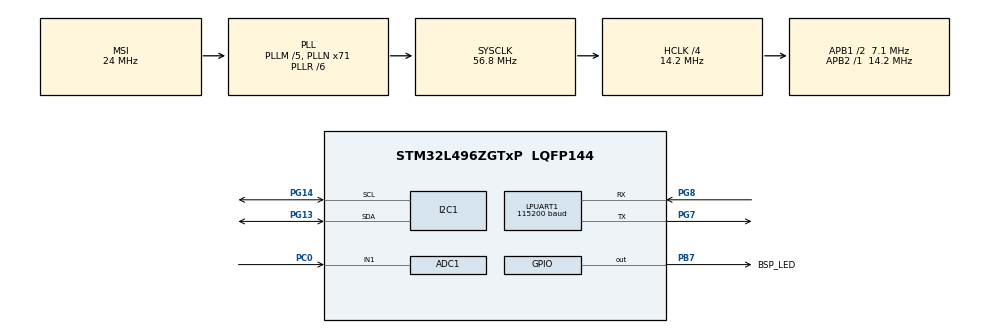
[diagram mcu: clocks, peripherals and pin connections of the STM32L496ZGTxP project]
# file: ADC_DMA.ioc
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ADC1.Channel-0\#ChannelRegularConversion=ADC_CHANNEL_1
ADC1.NbrOfConversionFlag=1
ADC1.OffsetNumber-0\#ChannelRegularConversion=ADC_OFFSET_NONE
ADC1.Rank-0\#ChannelRegularConversion=1
ADC1.SamplingTime-0\#ChannelRegularConversion=ADC_SAMPLETIME_2CYCLES_5
ADC1.master=1
Dma.ADC1.0.Direction=DMA_PERIPH_TO_MEMORY
Dma.ADC1.0.Instance=DMA1_Channel1
Dma.ADC1.0.MemDataAlignment=DMA_MDATAALIGN_WORD
Dma.ADC1.0.MemInc=DMA_MINC_ENABLE
Dma.ADC1.0.Mode=DMA_CIRCULAR
Dma.ADC1.0.PeriphDataAlignment=DMA_PDATAALIGN_WORD
Dma.ADC1.0.PeriphInc=DMA_PINC_DISABLE
Dma.ADC1.0.Priority=DMA_PRIORITY_LOW
Dma.Request0=ADC1
I2C1.Timing=0x00101A26
LPUART1.BaudRate=115200
LPUART1.WordLength=UART_WORDLENGTH_8B
Mcu.Family=STM32L4
Mcu.Name=STM32L496ZGTxP
Mcu.Package=LQFP144
NVIC.DMA1_Channel1_IRQn=true\:0\:0\:false\:false\:true\:false\:true\:true
NVIC.PriorityGroup=NVIC_PRIORITYGROUP_4
PB7.GPIO_Label=BSP_LED
PB7.Signal=GPIO_Output
PC0.Signal=ADCx_IN1
PG13.Mode=I2C
PG13.Signal=I2C1_SDA
PG14.Mode=I2C
PG14.Signal=I2C1_SCL
PG7.Mode=Asynchronous
PG7.Signal=LPUART1_TX
PG8.Mode=Asynchronous
PG8.Signal=LPUART1_RX
ProjectManager.HeapSize=0x200
ProjectManager.StackSize=0x400
ProjectManager.TargetToolchain=STM32CubeIDE
RCC.48MHZClocksFreq_Value=24000000
RCC.ADCFreq_Value=48000000
RCC.AHBCLKDivider=RCC_SYSCLK_DIV4
RCC.AHBFreq_Value=14200000
RCC.APB1CLKDivider=RCC_HCLK_DIV2
RCC.APB1Freq_Value=7100000
RCC.APB1TimFreq_Value=14200000
RCC.APB2Freq_Value=14200000
RCC.APB2TimFreq_Value=14200000
RCC.CortexFreq_Value=14200000
RCC.HCLKFreq_Value=14200000
RCC.HSE_VALUE=8000000
RCC.HSI48_VALUE=48000000
RCC.HSI_VALUE=16000000
RCC.LSE_VALUE=32768
RCC.MSIClockRange=RCC_MSIRANGE_9
RCC.MSI_VALUE=24000000
RCC.PLLM=5
RCC.PLLMUL=RCC_PLL_MUL9
RCC.PLLN=71
RCC.PLLR=RCC_PLLR_DIV6
RCC.PLLSAI1N=20
RCC.PRESCALERUSB=RCC_USBCLKSOURCE_PLL_DIV1_5
RCC.SYSCLKFreq_VALUE=56800000
RCC.SYSCLKSource=RCC_SYSCLKSOURCE_PLLCLK
RCC.SYSCLKSourceVirtual=RCC_SYSCLKSOURCE_PLLCLK
RCC.USBFreq_Value=48000000
RCC.VCOOutputFreq_Value=340800000
SH.ADCx_IN1.0=ADC1_IN1,IN1-Single-Ended
board=NUCLEO-L496ZG-P

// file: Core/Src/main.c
/* USER CODE BEGIN Header */
/**
 ******************************************************************************
 * @file           : main.c
 * @brief          : Main program body
 ******************************************************************************
 * @attention
 *
 * Copyright (c) 2023 STMicroelectronics.
 * All rights reserved.
 *
 * This software is licensed under terms that can be found in the LICENSE file
 * in the root directory of this software component.
 * If no LICENSE file comes with this software, it is provided AS-IS.
 *
 ******************************************************************************
 */
/* USER CODE END Header */
#include "main.h"

/* USER CODE BEGIN Includes */
#include<stdio.h>
/* USER CODE END Includes */

ADC_HandleTypeDef hadc1;
DMA_HandleTypeDef hdma_adc1;

I2C_HandleTypeDef hi2c1;

UART_HandleTypeDef hlpuart1;

/* USER CODE BEGIN PV */
uint32_t buffer;
/* USER CODE END PV */

void SystemClock_Config(void);
static void MX_GPIO_Init(void);
static void MX_DMA_Init(void);
static void MX_ADC1_Init(void);
static void MX_I2C1_Init(void);
static void MX_LPUART1_UART_Init(void);
/* USER CODE BEGIN PFP */
//void HAL_ADC_ConvCpltCallback(ADC_HandleTypeDef *hadc);
//void HAL_ADC_ConvHalfCpltCallback(ADC_HandleTypeDef *hadc);
/* USER CODE END PFP */

/* USER CODE BEGIN 0 */
uint32_t adc_val;
void HAL_ADC_ConvHalfCpltCallback(ADC_HandleTypeDef *hadc)
{
printf("intrupt\r\n");
}

void HAL_ADC_ConvCpltCallback(ADC_HandleTypeDef *hadc)

{
	printf("after this intrupt\r\n");
}

/* USER CODE END 0 */

int main(void)
{

  /* MCU Configuration--------------------------------------------------------*/

  /* Reset of all peripherals, Initializes the Flash interface and the Systick. */
  HAL_Init();

  /* Configure the system clock */
  SystemClock_Config();

  /* Initialize all configured peripherals */
  MX_GPIO_Init();
  MX_DMA_Init();
  MX_ADC1_Init();
  MX_I2C1_Init();
  MX_LPUART1_UART_Init();
  /* USER CODE BEGIN 2 */
	// HAL_ADC_Start_DMA (&hadc1, &buffer,1);//start in DMA mode we are redding only one chanal and one word
	printf("ADC DMA METHOD\n");
	 HAL_ADC_Start_DMA (&hadc1, &buffer,1);
  /* USER CODE END 2 */

  /* Infinite loop */
	while (1) {

    /* USER CODE BEGIN 3 */
	// HAL_ADC_Start_DMA (&hadc1, &buffer,1);
//	  HAL_Delay(500);
//	 // printf("adc_val:::: %d\n",adc_val);
//	  printf("buffer::::%d\n",buffer);
//	 HAL_Delay(500);
//	 HAL_ADC_Stop_DMA(&hadc1);
	}
  /* USER CODE END 3 */
}

void SystemClock_Config(void)
{
  RCC_OscInitTypeDef RCC_OscInitStruct = {0};
  RCC_ClkInitTypeDef RCC_ClkInitStruct = {0};

  /** Configure the main internal regulator output voltage
  */
  if (HAL_PWREx_ControlVoltageScaling(PWR_REGULATOR_VOLTAGE_SCALE1) != HAL_OK)
  {
    Error_Handler();
  }

  /** Initializes the RCC Oscillators according to the specified parameters
  * in the RCC_OscInitTypeDef structure.
  */
  RCC_OscInitStruct.OscillatorType = RCC_OSCILLATORTYPE_MSI;
  RCC_OscInitStruct.MSIState = RCC_MSI_ON;
  RCC_OscInitStruct.MSICalibrationValue = 0;
  RCC_OscInitStruct.MSIClockRange = RCC_MSIRANGE_9;
  RCC_OscInitStruct.PLL.PLLState = RCC_PLL_ON;
  RCC_OscInitStruct.PLL.PLLSource = RCC_PLLSOURCE_MSI;
  RCC_OscInitStruct.PLL.PLLM = 5;
  RCC_OscInitStruct.PLL.PLLN = 71;
  RCC_OscInitStruct.PLL.PLLP = RCC_PLLP_DIV2;
  RCC_OscInitStruct.PLL.PLLQ = RCC_PLLQ_DIV2;
  RCC_OscInitStruct.PLL.PLLR = RCC_PLLR_DIV6;
  if (HAL_RCC_OscConfig(&RCC_OscInitStruct) != HAL_OK)
  {
    Error_Handler();
  }

  /** Initializes the CPU, AHB and APB buses clocks
  */
  RCC_ClkInitStruct.ClockType = RCC_CLOCKTYPE_HCLK|RCC_CLOCKTYPE_SYSCLK
                              |RCC_CLOCKTYPE_PCLK1|RCC_CLOCKTYPE_PCLK2;
  RCC_ClkInitStruct.SYSCLKSource = RCC_SYSCLKSOURCE_PLLCLK;
  RCC_ClkInitStruct.AHBCLKDivider = RCC_SYSCLK_DIV4;
  RCC_ClkInitStruct.APB1CLKDivider = RCC_HCLK_DIV2;
  RCC_ClkInitStruct.APB2CLKDivider = RCC_HCLK_DIV1;

  if (HAL_RCC_ClockConfig(&RCC_ClkInitStruct, FLASH_LATENCY_0) != HAL_OK)
  {
    Error_Handler();
  }
}

static void MX_ADC1_Init(void)
{

  ADC_MultiModeTypeDef multimode = {0};
  ADC_ChannelConfTypeDef sConfig = {0};

  /** Common config
  */
  hadc1.Instance = ADC1;
  hadc1.Init.ClockPrescaler = ADC_CLOCK_ASYNC_DIV1;
  hadc1.Init.Resolution = ADC_RESOLUTION_12B;
  hadc1.Init.DataAlign = ADC_DATAALIGN_RIGHT;
  hadc1.Init.ScanConvMode = ADC_SCAN_DISABLE;
  hadc1.Init.EOCSelection = ADC_EOC_SINGLE_CONV;
  hadc1.Init.LowPowerAutoWait = DISABLE;
  hadc1.Init.ContinuousConvMode = DISABLE;
  hadc1.Init.NbrOfConversion = 1;
  hadc1.Init.DiscontinuousConvMode = DISABLE;
  hadc1.Init.ExternalTrigConv = ADC_SOFTWARE_START;
  hadc1.Init.ExternalTrigConvEdge = ADC_EXTERNALTRIGCONVEDGE_NONE;
  hadc1.Init.DMAContinuousRequests = DISABLE;
  hadc1.Init.Overrun = ADC_OVR_DATA_PRESERVED;
  hadc1.Init.OversamplingMode = DISABLE;
  if (HAL_ADC_Init(&hadc1) != HAL_OK)
  {
    Error_Handler();
  }

  /** Configure the ADC multi-mode
  */
  multimode.Mode = ADC_MODE_INDEPENDENT;
  if (HAL_ADCEx_MultiModeConfigChannel(&hadc1, &multimode) != HAL_OK)
  {
    Error_Handler();
  }

  /** Configure Regular Channel
  */
  sConfig.Channel = ADC_CHANNEL_1;
  sConfig.Rank = ADC_REGULAR_RANK_1;
  sConfig.SamplingTime = ADC_SAMPLETIME_2CYCLES_5;
  sConfig.SingleDiff = ADC_SINGLE_ENDED;
  sConfig.OffsetNumber = ADC_OFFSET_NONE;
  sConfig.Offset = 0;
  if (HAL_ADC_ConfigChannel(&hadc1, &sConfig) != HAL_OK)
  {
    Error_Handler();
  }

}

static void MX_I2C1_Init(void)
{

  hi2c1.Instance = I2C1;
  hi2c1.Init.Timing = 0x00101A26;
  hi2c1.Init.OwnAddress1 = 0;
  hi2c1.Init.AddressingMode = I2C_ADDRESSINGMODE_7BIT;
  hi2c1.Init.DualAddressMode = I2C_DUALADDRESS_DISABLE;
  hi2c1.Init.OwnAddress2 = 0;
  hi2c1.Init.OwnAddress2Masks = I2C_OA2_NOMASK;
  hi2c1.Init.GeneralCallMode = I2C_GENERALCALL_DISABLE;
  hi2c1.Init.NoStretchMode = I2C_NOSTRETCH_DISABLE;
  if (HAL_I2C_Init(&hi2c1) != HAL_OK)
  {
    Error_Handler();
  }

  /** Configure Analogue filter
  */
  if (HAL_I2CEx_ConfigAnalogFilter(&hi2c1, I2C_ANALOGFILTER_ENABLE) != HAL_OK)
  {
    Error_Handler();
  }

  /** Configure Digital filter
  */
  if (HAL_I2CEx_ConfigDigitalFilter(&hi2c1, 0) != HAL_OK)
  {
    Error_Handler();
  }

}

static void MX_LPUART1_UART_Init(void)
{

  hlpuart1.Instance = LPUART1;
  hlpuart1.Init.BaudRate = 115200;
  hlpuart1.Init.WordLength = UART_WORDLENGTH_8B;
  hlpuart1.Init.StopBits = UART_STOPBITS_1;
  hlpuart1.Init.Parity = UART_PARITY_NONE;
  hlpuart1.Init.Mode = UART_MODE_TX_RX;
  hlpuart1.Init.HwFlowCtl = UART_HWCONTROL_NONE;
  hlpuart1.Init.OneBitSampling = UART_ONE_BIT_SAMPLE_DISABLE;
  hlpuart1.AdvancedInit.AdvFeatureInit = UART_ADVFEATURE_NO_INIT;
  if (HAL_UART_Init(&hlpuart1) != HAL_OK)
  {
    Error_Handler();
  }

}

static void MX_DMA_Init(void)
{

  /* DMA controller clock enable */
  __HAL_RCC_DMA1_CLK_ENABLE();

  /* DMA interrupt init */
  /* DMA1_Channel1_IRQn interrupt configuration */
  HAL_NVIC_SetPriority(DMA1_Channel1_IRQn, 0, 0);
  HAL_NVIC_EnableIRQ(DMA1_Channel1_IRQn);

}

static void MX_GPIO_Init(void)
{
  GPIO_InitTypeDef GPIO_InitStruct = {0};

  /* GPIO Ports Clock Enable */
  __HAL_RCC_GPIOC_CLK_ENABLE();
  __HAL_RCC_GPIOG_CLK_ENABLE();
  HAL_PWREx_EnableVddIO2();
  __HAL_RCC_GPIOB_CLK_ENABLE();

  /*Configure GPIO pin Output Level */
  HAL_GPIO_WritePin(BSP_LED_GPIO_Port, BSP_LED_Pin, GPIO_PIN_RESET);

  /*Configure GPIO pin : BSP_LED_Pin */
  GPIO_InitStruct.Pin = BSP_LED_Pin;
  GPIO_InitStruct.Mode = GPIO_MODE_OUTPUT_PP;
  GPIO_InitStruct.Pull = GPIO_NOPULL;
  GPIO_InitStruct.Speed = GPIO_SPEED_FREQ_LOW;
  HAL_GPIO_Init(BSP_LED_GPIO_Port, &GPIO_InitStruct);

}

void Error_Handler(void)
{
	__disable_irq();
	while (1) {
	}
}
